# iME register map
Vendor: Texas Instruments
Peripheral module from a debugger description file (folder omap36xx).
Registers are 32-bit, read-write, no defined reset value unless marked. A register's access mark holds for its fields unless they carry their own. Offsets are as the file gives them; lines under a group give offsets from that group; [hi:lo] are bit positions; {n}, {i} and the like mark numbered series; 'fields as' and 'values as' point back to an identical list; <NAME> marks a mode.

## iME
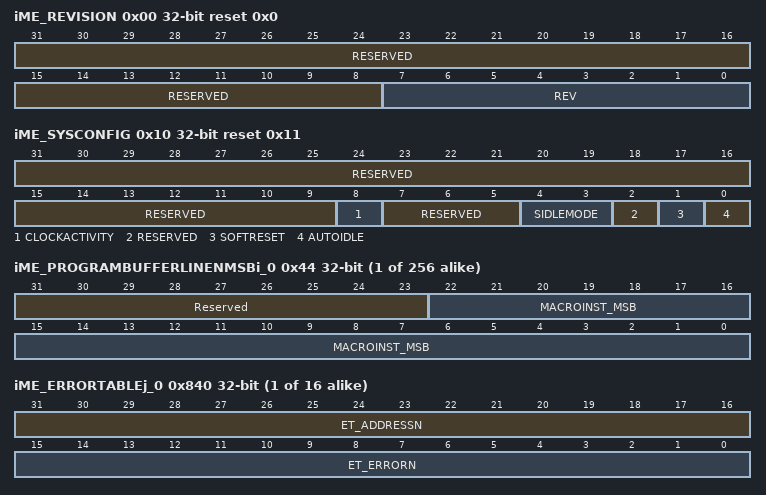
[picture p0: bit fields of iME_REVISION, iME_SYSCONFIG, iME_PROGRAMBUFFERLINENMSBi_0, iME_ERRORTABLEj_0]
0x00 iME_REVISION ro reset 0x0 (reset mask 0xFFFFFF00) — This register contains the iME revision code
  [31:8] RESERVED — Read returns 0
  [7:0] REV — iME Revision[3:0] Minor Revision[7:4] Major Revision
0x10 iME_SYSCONFIG access per field reset 0x11 — This register allows controlling various parameters of the OCP interface
  [31:9] RESERVED ro — Read returns 0.
  [8] CLOCKACTIVITY ro — Clock activity during wake up mode period. 0 - OCP clock can be switched-off.
  [7:5] RESERVED ro — Read returns 0.
  [4:3] SIDLEMODE ro — Slave interface power management, req/ack control '10' = Smart-idle. Acknowledgement to an idle request is given based on the internal activity of iME
  [2] RESERVED ro — Read returns 0.
  [1] SOFTRESET rw — Software reset. Set this bit to 1 to trigger the iME reset.The bit is automatically reset by the hardware. During reads, it always returns 0.
  [0] AUTOIDLE rw — Internal OCP clock gating strategy: 0: OCP clock is free running 1: Automatic OCP clock-gating strategy is applied based on the OCP interface activity
0x14 iME_SYSSTATUS ro reset 0x0 (reset mask 0xFFFFFFFE) — The register provides status information about the module, excluding the interrupt information.
  [0] RESETDONE — Internal reset monitoring 0: Internal module reset is on-going 1: Reset completed
{0x40+8i} iME_PROGRAMBUFFERLINENLSBi_{i} (i=0..255) — Lower part of the macro-instruction : bits [31:0]
  [31:0] MACROINST_LSB — Line i of 256, Lower part of the macro-instruction : bits [31:0]
{0x44+8i} iME_PROGRAMBUFFERLINENMSBi_{i} access per field (i=0..255) — High part of the macro-instruction : bits [54:32]
  [31:23] Reserved ro — Read returns 0
  [22:0] MACROINST_MSB rw — Line i of 256, high part of the macro-instruction : bits [54:32]
{0x840+4i} iME_ERRORTABLEj_{i} (i=0..15) — Register file (Error Table) for SAD computation containing final errors. Each entry in the register comprises a 16-bit Error field and a 16-bit Address field.
  [31:16] ET_ADDRESSN — Error Table line i, Address value
  [15:0] ET_ERRORN — Error Table line i, Error value
{0x880+4i} iME_REFERENCEBLOCKk_{i} (i=0..63) — 16 lines of 16 bytes register file containing the reference block data for SAD computation.
  [31:0] REFBLOCK_WORD — This word contains 4 pixels.
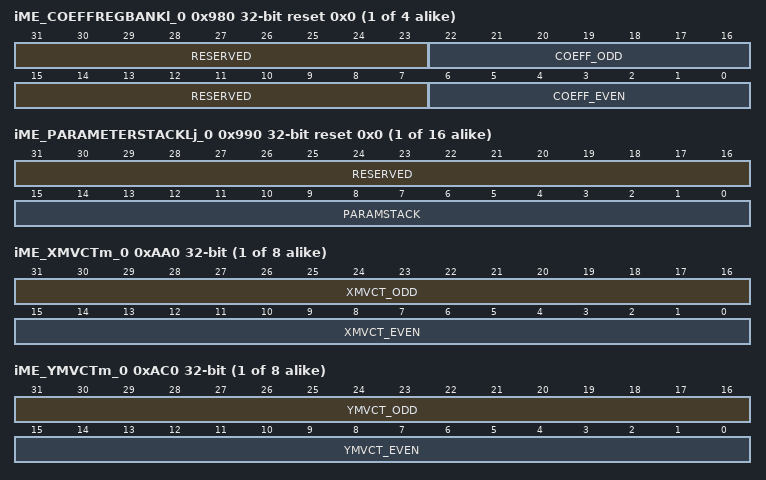
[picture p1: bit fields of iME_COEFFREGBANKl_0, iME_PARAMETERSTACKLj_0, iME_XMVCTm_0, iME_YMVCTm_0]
{0x980+4i} iME_COEFFREGBANKl_{i} reset 0x0 (reset mask 0xFF80FF80) (i=0..3) — Coefficients Register Bank: The coefficient is 7 bit wide and 2 coefficients are stored in one word in the following format: [31:23] = 0x00 [22:16] = Coeff_odd [15:7] = 0x00 [6:0] = Coeff_even
  [31:23] RESERVED — Read returns 0.
  [22:16] COEFF_ODD — Coefficient (odd index)
  [15:7] RESERVED — read returns 0.
  [6:0] COEFF_EVEN — Coefficient (even index)
{0x990+4i} iME_PARAMETERSTACKLj_{i} access per field reset 0x0 (reset mask 0xFFFF0000) (i=0..15) — Parameter stack register 0 to 15 (16-bit wide). Contains parameters used by program to control the iME units.
  [31:16] RESERVED ro — Read returns zero.
  [15:0] PARAMSTACK rw — Parameter of 0 to 15
{0x9D0+4i} iME_PARAMETERSTACKHj_{i} (i=0..15) — Parameter stack register 16 to 31 (32-bit wide). Contains parameters used by program to control the iMEunits.
  [31:0] PARAMSTACK — Parameter of 16 to 31
{0xAA0+4i} iME_XMVCTm_{i} (i=0..7) — Two Motion Vector Cost value (16-bits wide) are packed in one 32 bit word.
  [31:16] XMVCT_ODD — MV Cost value of odd index
  [15:0] XMVCT_EVEN — MV Cost value of even index
{0xAC0+4i} iME_YMVCTm_{i} (i=0..7) — Two Motion Vector Cost value (16-bits wide) are packed in one 32 bit word.
  [31:16] YMVCT_ODD — MV Cost value of odd index
  [15:0] YMVCT_EVEN — MV Cost value of even index
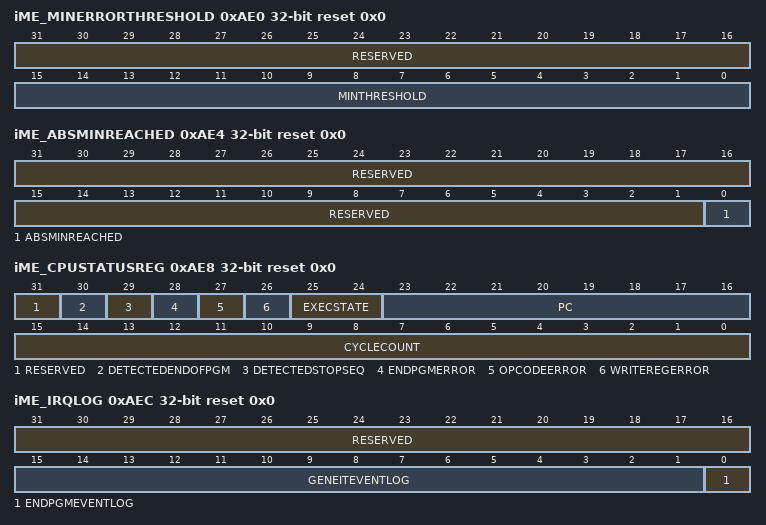
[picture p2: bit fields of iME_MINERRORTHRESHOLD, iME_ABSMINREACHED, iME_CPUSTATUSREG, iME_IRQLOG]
0xAE0 iME_MINERRORTHRESHOLD access per field reset 0x0 (reset mask 0xFFFF0000) — Minimum Error Threshold register, used in Mcomp() operator.
  [31:16] RESERVED ro — Read returns 0.
  [15:0] MINTHRESHOLD rw — Min Threshold value in Mcomp() block.
0xAE4 iME_ABSMINREACHED access per field reset 0x0 (reset mask 0xFFFFFFFE) — Absolute Minimum Reached bit register, used in Mcomp() operator.
  [31:1] RESERVED ro — Read returns 0.
  [0] ABSMINREACHED rw — Abs Min Reached bit, in Mcomp block.
0xAE8 iME_CPUSTATUSREG ro reset 0x0 — CPU Status Register provides information about the progress of the CPU execution
  [31] RESERVED — read returns 0.
  [30] DETECTEDENDOFPGM — This bit is set to '1' when in Debug mode, an EndOfPgm instruction or the last instruction of ProgramBuffer has been reached.
  [29] DETECTEDSTOPSEQ — This bit is set to '1' when a StopSeq() command has been issued and the iME is in Halted state.
  [28] ENDPGMERROR — This bit is set to '1' when the last instruction of the Program Buffer is reached, and no EndPgm() or LoadInstBuf() instruction have been detected in the program buffer.This bit is cleared by a StartSeq() command.
  [27] OPCODEERROR — This bit is set to '1' when a unknown opcode is decoded from the main program.This bit is cleared by StartSeq() command when in INITIALIZED state, or by a Stop() command.
  [26] WRITEREGERROR — This bit is set to '1' when attempting to write to an internal register through an OCP Write, while in EXECUTING state.This bit is cleared by StartSeq() command when in INITIALIZED state, or by a Stop() command.
  [25:24] EXECSTATE — Execution States:00 = Initialized,10 = Executing,01 = Halted,11 = Completed.
  [23:16] PC — Number of instruction currently executing.
  [15:0] CYCLECOUNT — Total number of cycles executed.
0xAEC iME_IRQLOG ro reset 0x0 — IRQ Log register captures a one on bit 0 if the endpgm() instruction has been executed and a one on bits 1 to 15 for the first 15 GenerateIT() instructions executed (beyond 15, GenerateIT() events are logged into bit 15)
  [31:16] RESERVED — Read returns 0.
  [15:1] GENEITEVENTLOG — GenerateIT() instructions event log
  [0] ENDPGMEVENTLOG — endpgm() instruction event log.
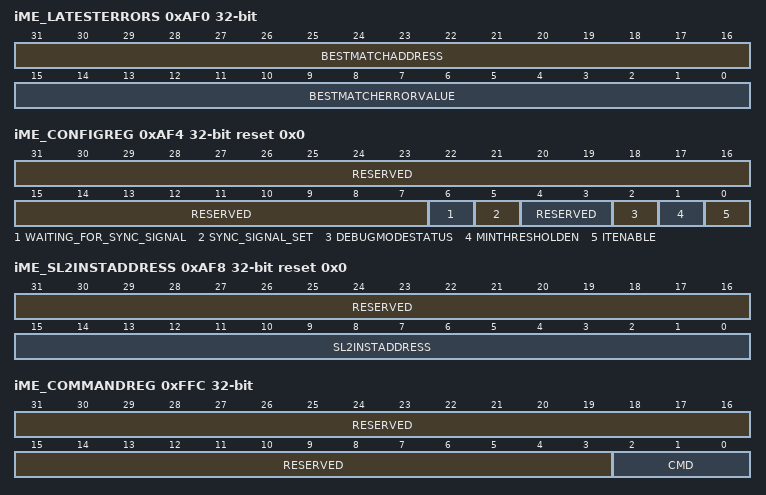
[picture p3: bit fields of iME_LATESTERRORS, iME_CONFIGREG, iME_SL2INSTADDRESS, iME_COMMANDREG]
0xAF0 iME_LATESTERRORS — Best Match Location ( minimum error) data and its address generated by Multi compare unit
  [31:16] BESTMATCHADDRESS — Best Match Error Address
  [15:0] BESTMATCHERRORVALUE
0xAF4 iME_CONFIGREG access per field reset 0x0 — Configuration Register
  [31:7] RESERVED ro — read returns 0.
  [6] WAITING_FOR_SYNC_SIGNAL ro — Bit is set when the WaitForSignal instruction has been decoded.
  [5] SYNC_SIGNAL_SET ro — Bit is set when iME has received the synchronisation signal.
  [4:3] RESERVED ro — read returns 0.
  [2] DEBUGMODESTATUS ro — 'Debug Mode' status bit
  [1] MINTHRESHOLDEN rw — Enable Min Threshold Comparison bit
  [0] ITENABLE rw — Interrupt Enable bit
0xAF8 iME_SL2INSTADDRESS access per field reset 0x0 — This register contains the SL2 address passed in the instruction.
  [31:16] RESERVED ro — Read returns 0.
  [15:0] SL2INSTADDRESS rw — This register contains the SL2 address passed in the instruction.
0xFFC iME_COMMANDREG wo — iME command register: a write to this register decodes a command, a read returns an error. 0x1 -> StartSeq() 0x2 -> StopSeq() 0x3 -> DbgEnable() 0x4 -> DbgDisable() 0x5 -> DbgStep() 0x6 -> Halt()
  [31:3] RESERVED — Read returns an error
  [2:0] CMD — DATA/COMMAND 0x1 -&gt; StartSeq() 0x2 -&gt; StopSeq() 0x3 -&gt; DbgEnable() 0x4 -&gt; DbgDisable() 0x5 -&gt; DbgStep() 0x6 -&gt; Halt()0x7 -&gt; Sync()
